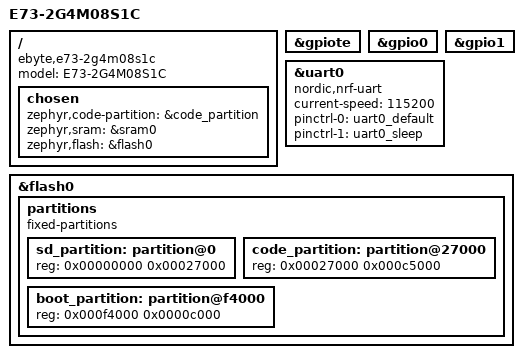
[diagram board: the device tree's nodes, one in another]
/*
 * SPDX-License-Identifier: MIT
 */

#include <nordic/nrf52840_qiaa.dtsi>

/ {
  model = "E73-2G4M08S1C";
  compatible = "ebyte,e73-2g4m08s1c";

  chosen {
    zephyr,code-partition = &code_partition;
    zephyr,sram = &sram0;
    zephyr,flash = &flash0;
  };
};

// Stuff that might need to be included at some point:
// - &adc
// - &i2c0
// - &spi1
// - &uart0
// - &usbd

&gpiote {
  status = "okay";
};

&gpio0 {
  status = "okay";
};

&gpio1 {
  status = "okay";
};

&uart0 {
  status = "okay";
  compatible = "nordic,nrf-uart";
  current-speed = <115200>;
  pinctrl-0 = <&uart0_default>;
  pinctrl-1 = <&uart0_sleep>;
  pinctrl-names = "default", "sleep";
};

&flash0 {
  partitions {
    compatible = "fixed-partitions";
    #address-cells = <1>;
    #size-cells = <1>;

    sd_partition: partition@0 {
      reg = <0x00000000 0x00027000>;
    };
    code_partition: partition@27000 {
      reg = <0x00027000 0x000c5000>;
    };

    boot_partition: partition@f4000 {
      reg = <0x000f4000 0x0000c000>;
    };
  };
};

